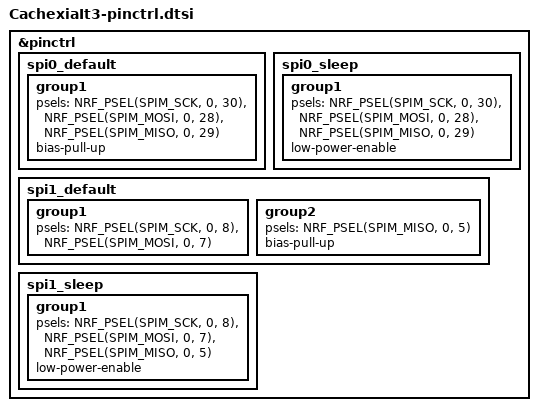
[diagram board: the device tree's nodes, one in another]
&pinctrl {
    spi0_default: spi0_default {
        group1 {
            psels = <NRF_PSEL(SPIM_SCK, 0, 30)>,
                <NRF_PSEL(SPIM_MOSI, 0, 28)>,
                <NRF_PSEL(SPIM_MISO, 0, 29)>;
            bias-pull-up;   /* 关键：给 MISO 上拉（注意：这会对该 group 里的所有 pin 生效） */
        };
    };

    spi0_sleep: spi0_sleep {
        group1 {
            psels = <NRF_PSEL(SPIM_SCK, 0, 30)>,
                <NRF_PSEL(SPIM_MOSI, 0, 28)>,
                <NRF_PSEL(SPIM_MISO, 0, 29)>;
            low-power-enable;
        };
    };

    /* ---- BMI270 on SPI1 ----
     *  imu_sck  = P0.08
     *  imu_mosi = P0.07
     *  imu_miso = P0.05
     */
    spi1_default: spi1_default {
        group1 {
            psels = <NRF_PSEL(SPIM_SCK, 0, 8)>,
                <NRF_PSEL(SPIM_MOSI, 0, 7)>;
        };
        group2 {
            psels = <NRF_PSEL(SPIM_MISO, 0, 5)>;
            bias-pull-up;   /* 可选：让 MISO 在 CS 高时不漂（只对 MISO 生效） */
        };
    };

    spi1_sleep: spi1_sleep {
        group1 {
            psels = <NRF_PSEL(SPIM_SCK, 0, 8)>,
                <NRF_PSEL(SPIM_MOSI, 0, 7)>,
                <NRF_PSEL(SPIM_MISO, 0, 5)>;
            low-power-enable;
        };
    };
};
